AUTOSAR XML (schema 4-0-3)
standard types defined: UInt32, UInt8
package /AUTOSAR_Platform/DataConstrs
  range DC_UInt8: raw 0..255
package /PATAC/MSM/ComponentTypes
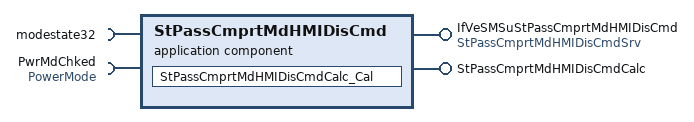
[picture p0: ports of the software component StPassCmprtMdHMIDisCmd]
  application sw component type StPassCmprtMdHMIDisCmd
    provide port IfVeSMSuStPassCmprtMdHMIDisCmd: nonqueued-sender-com-spec=data-element=StPassCmprtMdHMIDisCmdSrv/Val, provided-interface=StPassCmprtMdHMIDisCmdSrv
    provide port StPassCmprtMdHMIDisCmdCalc: server-com-spec{operation=Cal, queue-length=1}, provided-interface=StPassCmprtMdHMIDisCmdCalc
    require port modestate32: nonqueued-receiver-com-spec{data-element=modestate32/Val, filter=data-filter-type=ALWAYS, init-value=0}, required-interface=modestate32
    require port PwrMdChked: nonqueued-receiver-com-spec{data-element=PowerMode/Val, filter=data-filter-type=ALWAYS}, required-interface=PowerMode
    behavior StPassCmprtMdHMIDisCmd_InternalBehavior
      operation invoked event OIT_StPassCmprtMdHMIDisCmdCalc_Cal_StPassCmprtMdHMIDisCmdCalc_Cal: start-on-event=StPassCmprtMdHMIDisCmdCalc_Cal, operation=StPassCmprtMdHMIDisCmdCalc.Cal
      runnable StPassCmprtMdHMIDisCmdCalc_Cal
        data-receive-point-by-arguments:
          access REC_modestate32_Val: accessed-variable=modestate32.Val
          access REC_PwrMdChked_Val: accessed-variable=PwrMdChked.Val
        data-send-points:
          access SEND_IfVeSMSuStPassCmprtMdHMIDisCmd_Val: accessed-variable=IfVeSMSuStPassCmprtMdHMIDisCmd.Val
  swc implementation StPassCmprtMdHMIDisCmd_Implementation: behavior=StPassCmprtMdHMIDisCmd_InternalBehavior
    code-descriptors:
      code Default: artifact-descriptors=autosar-engineering-object={short-label=Default, category=SWSRC}
package /PATAC/MSM/ModeAdjust/DataType
  impl type PowerMode1: category=VALUE, base-type=UInt8, sw-calibration-access=READ-ONLY, compu {0=PowerMode_Off, 1=PowerMode_Acc, 2=PowerMode_Run, 3=PowerMode_Crank, 4=PowerMode_Invalid}, type-emitter=RTE
package /PATAC/MSM/ModeAdjust/PortInterface
  client server interface StPassCmprtMdHMIDisCmdCalc
    operation Cal
  sender receiver interface modestate32: invalidation-policy{data-element=modestate32/Val, handle-invalid=DONT-INVALIDATE}
    data Val: type=UInt32
  sender receiver interface PowerMode: invalidation-policy{data-element=PowerMode/Val, handle-invalid=DONT-INVALIDATE}
    data Val: type=PowerMode1
  sender receiver interface StPassCmprtMdHMIDisCmdSrv: invalidation-policy{data-element=StPassCmprtMdHMIDisCmdSrv/Val, handle-invalid=DONT-INVALIDATE}
    data Val: type=UInt8
